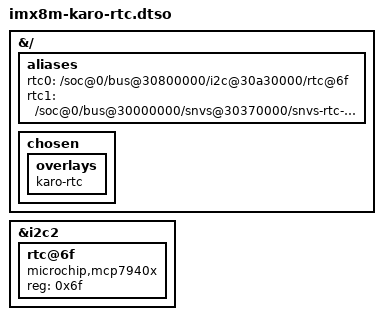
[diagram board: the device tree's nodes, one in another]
// SPDX-License-Identifier: (GPL-2.0 OR BSD-3-Clause)
/*
 * Copyright (C) 2022 Lothar Waßmann <LW@KARO-electronics.de>
 */

/dts-v1/;
/plugin/;

&{/} {
	aliases {
		rtc0 = "/soc@0/bus@30800000/i2c@30a30000/rtc@6f";
		rtc1 = "/soc@0/bus@30000000/snvs@30370000/snvs-rtc-lp";
	};

	chosen {
		overlays {
			karo-rtc;
		};
	};
};

&i2c2 {
	#address-cells = <1>;
	#size-cells = <0>;
	status = "okay";

	rtc@6f {
		compatible = "microchip,mcp7940x";
		reg = <0x6f>;
		status = "okay";
	};
};
